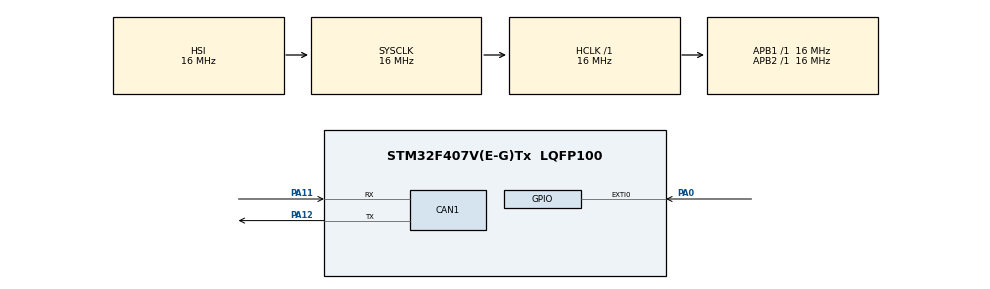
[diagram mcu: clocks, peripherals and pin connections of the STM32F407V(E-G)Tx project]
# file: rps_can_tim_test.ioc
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CAN1.CalculateTimeBit=3000
CAN1.CalculateTimeQuantum=1000.0
Mcu.Family=STM32F4
Mcu.Name=STM32F407V(E-G)Tx
Mcu.Package=LQFP100
NVIC.EXTI0_IRQn=true\:0\:0\:false\:false\:true
NVIC.PriorityGroup=NVIC_PRIORITYGROUP_4
PA0-WKUP.GPIO_ModeDefaultEXTI=GPIO_MODE_IT_RISING_FALLING
PA0-WKUP.GPIO_PuPd=GPIO_PULLUP
PA0-WKUP.Signal=GPXTI0
PA11.Mode=Master
PA11.Signal=CAN1_RX
PA12.Mode=Master
PA12.Signal=CAN1_TX
ProjectManager.HeapSize=0x200
ProjectManager.StackSize=0x400
ProjectManager.TargetToolchain=SW4STM32
RCC.AHBFreq_Value=16000000
RCC.APB1Freq_Value=16000000
RCC.APB2Freq_Value=16000000
RCC.CortexFreq_Value=16000000
RCC.HSE_VALUE=25000000
RCC.HSI_VALUE=16000000
RCC.LSE_VALUE=32768
RCC.SYSCLKFreq_VALUE=16000000
RCC.VCOOutputFreq_Value=192000000
VP_TIM3_VS_ClockSourceINT.Mode=Internal
board=rps_can_tim_test

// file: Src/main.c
/**
  ******************************************************************************
  * File Name          : main.c
  * Description        : Main program body
  ******************************************************************************
  *
  * COPYRIGHT(c) 2016 STMicroelectronics
  *
  * Redistribution and use in source and binary forms, with or without modification,
  * are permitted provided that the following conditions are met:
  *   1. Redistributions of source code must retain the above copyright notice,
  *      this list of conditions and the following disclaimer.
  *   2. Redistributions in binary form must reproduce the above copyright notice,
  *      this list of conditions and the following disclaimer in the documentation
  *      and/or other materials provided with the distribution.
  *   3. Neither the name of STMicroelectronics nor the names of its contributors
  *      may be used to endorse or promote products derived from this software
  *      without specific prior written permission.
  *
  * THIS SOFTWARE IS PROVIDED BY THE COPYRIGHT HOLDERS AND CONTRIBUTORS "AS IS"
  * AND ANY EXPRESS OR IMPLIED WARRANTIES, INCLUDING, BUT NOT LIMITED TO, THE
  * IMPLIED WARRANTIES OF MERCHANTABILITY AND FITNESS FOR A PARTICULAR PURPOSE ARE
  * DISCLAIMED. IN NO EVENT SHALL THE COPYRIGHT HOLDER OR CONTRIBUTORS BE LIABLE
  * FOR ANY DIRECT, INDIRECT, INCIDENTAL, SPECIAL, EXEMPLARY, OR CONSEQUENTIAL
  * DAMAGES (INCLUDING, BUT NOT LIMITED TO, PROCUREMENT OF SUBSTITUTE GOODS OR
  * SERVICES; LOSS OF USE, DATA, OR PROFITS; OR BUSINESS INTERRUPTION) HOWEVER
  * CAUSED AND ON ANY THEORY OF LIABILITY, WHETHER IN CONTRACT, STRICT LIABILITY,
  * OR TORT (INCLUDING NEGLIGENCE OR OTHERWISE) ARISING IN ANY WAY OUT OF THE USE
  * OF THIS SOFTWARE, EVEN IF ADVISED OF THE POSSIBILITY OF SUCH DAMAGE.
  *
  ******************************************************************************
  */
#include "stm32f4xx_hal.h"

/* USER CODE BEGIN Includes */
#include "canid.h"
#include "main.h"
#define calc 4
#define toothcount 48
#define BOARDID 0x06
uint32_t calculation_intervall = calc;
uint8_t interation = 4;
uint32_t tooth_[calc];
uint32_t timerValue = 0;
/* USER CODE END Includes */

CAN_HandleTypeDef hcan1;
TIM_HandleTypeDef htim3;

/* USER CODE BEGIN PV */
/* Private variables ---------------------------------------------------------*/
/* USER CODE END PV */

void SystemClock_Config(void);
void Error_Handler(void);
static void MX_GPIO_Init(void);
static void MX_CAN1_Init(void);
static void MX_TIM3_Init(void);

/* USER CODE BEGIN PFP */
/* Private function prototypes -----------------------------------------------*/
/* USER CODE END PFP */

int main(void)
{

  /* USER CODE BEGIN 1 */
	//CanTxMsg TxMsg;
  /* USER CODE END 1 */

  /* MCU Configuration----------------------------------------------------------*/

  /* Reset of all peripherals, Initializes the Flash interface and the Systick. */
  HAL_Init();

  /* Configure the system clock */
  SystemClock_Config();

  /* Initialize all configured peripherals */
  MX_GPIO_Init();
  MX_CAN1_Init();
  MX_TIM3_Init();

  /* USER CODE BEGIN 2 */

  for (int i = 0; i < calculation_intervall; i++){
  	tooth_[i] = 0;
  }
  //hcan1.pTxMsg->IDE = CAN_Id_Standard;
  hcan1.pTxMsg->RTR = CAN_RTR_DATA;
  hcan1.pTxMsg->StdId = 0x441;
  hcan1.pTxMsg->DLC = 1;
  hcan1.pTxMsg->Data[0] = 123;
  HAL_TIM_Base_Start(&htim3);
  /* USER CODE END 2 */

  /* Infinite loop */
  while (1)
  {

  /* USER CODE BEGIN 3 */
/*
	  if((__HAL_TIM_GetCounter(&htim3) - timerValue) >= (1 / toothcount)){
	  	  	sendMSG(0, 123, 1);
	  	  	HAL_Delay(5);
	  	  }
	  	  */
  }
  /* USER CODE END 3 */

}

/** System Clock Configuration
*/
void SystemClock_Config(void)
{

  RCC_OscInitTypeDef RCC_OscInitStruct;
  RCC_ClkInitTypeDef RCC_ClkInitStruct;

  __HAL_RCC_PWR_CLK_ENABLE();

  __HAL_PWR_VOLTAGESCALING_CONFIG(PWR_REGULATOR_VOLTAGE_SCALE1);

  RCC_OscInitStruct.OscillatorType = RCC_OSCILLATORTYPE_HSI;
  RCC_OscInitStruct.HSIState = RCC_HSI_ON;
  RCC_OscInitStruct.HSICalibrationValue = 16;
  RCC_OscInitStruct.PLL.PLLState = RCC_PLL_NONE;
  if (HAL_RCC_OscConfig(&RCC_OscInitStruct) != HAL_OK)
  {
    Error_Handler();
  }

  RCC_ClkInitStruct.ClockType = RCC_CLOCKTYPE_HCLK|RCC_CLOCKTYPE_SYSCLK
                              |RCC_CLOCKTYPE_PCLK1|RCC_CLOCKTYPE_PCLK2;
  RCC_ClkInitStruct.SYSCLKSource = RCC_SYSCLKSOURCE_HSI;
  RCC_ClkInitStruct.AHBCLKDivider = RCC_SYSCLK_DIV1;
  RCC_ClkInitStruct.APB1CLKDivider = RCC_HCLK_DIV1;
  RCC_ClkInitStruct.APB2CLKDivider = RCC_HCLK_DIV1;
  if (HAL_RCC_ClockConfig(&RCC_ClkInitStruct, FLASH_LATENCY_0) != HAL_OK)
  {
    Error_Handler();
  }

  HAL_SYSTICK_Config(HAL_RCC_GetHCLKFreq()/1000);

  HAL_SYSTICK_CLKSourceConfig(SYSTICK_CLKSOURCE_HCLK);

  /* SysTick_IRQn interrupt configuration */
  HAL_NVIC_SetPriority(SysTick_IRQn, 0, 0);
}

/* CAN1 init function */
static void MX_CAN1_Init(void)
{

  hcan1.Instance = CAN1;
  hcan1.Init.Prescaler = 16;
  hcan1.Init.Mode = CAN_MODE_NORMAL;
  hcan1.Init.SJW = CAN_SJW_1TQ;
  hcan1.Init.BS1 = CAN_BS1_1TQ;
  hcan1.Init.BS2 = CAN_BS2_1TQ;
  hcan1.Init.TTCM = DISABLE;
  hcan1.Init.ABOM = DISABLE;
  hcan1.Init.AWUM = DISABLE;
  hcan1.Init.NART = DISABLE;
  hcan1.Init.RFLM = DISABLE;
  hcan1.Init.TXFP = DISABLE;
  if (HAL_CAN_Init(&hcan1) != HAL_OK)
  {
    Error_Handler();
  }

}

/* TIM3 init function */
static void MX_TIM3_Init(void)
{

  TIM_ClockConfigTypeDef sClockSourceConfig;
  TIM_MasterConfigTypeDef sMasterConfig;

  htim3.Instance = TIM3;
  htim3.Init.Prescaler = 0;
  htim3.Init.CounterMode = TIM_COUNTERMODE_UP;
  htim3.Init.Period = 0;
  htim3.Init.ClockDivision = TIM_CLOCKDIVISION_DIV1;
  if (HAL_TIM_Base_Init(&htim3) != HAL_OK)
  {
    Error_Handler();
  }

  sClockSourceConfig.ClockSource = TIM_CLOCKSOURCE_INTERNAL;
  if (HAL_TIM_ConfigClockSource(&htim3, &sClockSourceConfig) != HAL_OK)
  {
    Error_Handler();
  }

  sMasterConfig.MasterOutputTrigger = TIM_TRGO_RESET;
  sMasterConfig.MasterSlaveMode = TIM_MASTERSLAVEMODE_DISABLE;
  if (HAL_TIMEx_MasterConfigSynchronization(&htim3, &sMasterConfig) != HAL_OK)
  {
    Error_Handler();
  }

}

/** Configure pins as
        * Analog
        * Input
        * Output
        * EVENT_OUT
        * EXTI
*/
static void MX_GPIO_Init(void)
{

  GPIO_InitTypeDef GPIO_InitStruct;

  /* GPIO Ports Clock Enable */
  __HAL_RCC_GPIOA_CLK_ENABLE();

  /*Configure GPIO pin : PA0 */
  GPIO_InitStruct.Pin = GPIO_PIN_0;
  GPIO_InitStruct.Mode = GPIO_MODE_IT_RISING_FALLING;
  GPIO_InitStruct.Pull = GPIO_PULLUP;
  HAL_GPIO_Init(GPIOA, &GPIO_InitStruct);

}

/* USER CODE BEGIN 4 */
void sendMSG(uint32_t MSG, uint32_t ID, uint8_t DLC) {
	hcan1.pTxMsg->StdId = ID;
	hcan1.pTxMsg->DLC = DLC;
	hcan1.pTxMsg->Data[0] = 123;
	HAL_CAN_Transmit(&hcan1, 1);
}
void rps_interrupt(void){
	timerValue = __HAL_TIM_GetCounter(&htim3);
		if (interation <= calculation_intervall && interation >= 0){
			tooth_[interation] = (__HAL_TIM_GetCounter(&htim3) - timerValue);
			interation++;
		}else{
//using a loop takes a bit of time, but it allows us to calculate rps with like 100tooth, yeah i know it kinda useless
			uint32_t subtotal = 0;
			for(int i = 0; i < calculation_intervall; i++){
				subtotal = subtotal + tooth_[i];
			}
			uint32_t USec = 1000/((subtotal / calculation_intervall) * 20);
			interation = 0;
			sendMSG(USec, CAN_ID_ECU_N_RPM_R, 1);
		}
}
/* USER CODE END 4 */

void Error_Handler(void)
{
  while(1)
  {
  }
}

/************************ (C) COPYRIGHT STMicroelectronics *****END OF FILE****/
